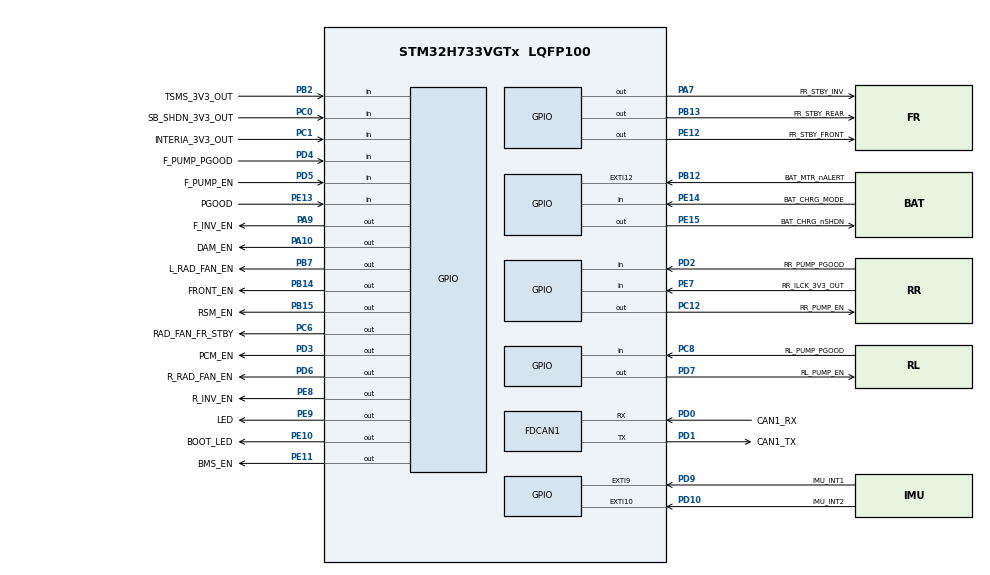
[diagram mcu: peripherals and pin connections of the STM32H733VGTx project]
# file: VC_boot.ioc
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FDCAN1.AutoRetransmission=ENABLE
FDCAN1.CalculateBaudRateNominal=1000000
FDCAN1.CalculateTimeBitNominal=1000
FDCAN1.CalculateTimeQuantumNominal=62.5
FDCAN1.DataPrescaler=3
FDCAN1.DataSyncJumpWidth=2
FDCAN1.DataTimeSeg1=5
FDCAN1.DataTimeSeg2=2
FDCAN1.ExtFiltersNbr=1
FDCAN1.FrameFormat=FDCAN_FRAME_FD_NO_BRS
FDCAN1.NominalPrescaler=6
FDCAN1.NominalSyncJumpWidth=2
FDCAN1.NominalTimeSeg1=12
FDCAN1.NominalTimeSeg2=3
FDCAN1.ProtocolException=DISABLE
FDCAN1.RxBufferSize=FDCAN_DATA_BYTES_64
FDCAN1.RxFifo0ElmtSize=FDCAN_DATA_BYTES_64
FDCAN1.RxFifo0ElmtsNbr=1
FDCAN1.RxFifo1ElmtSize=FDCAN_DATA_BYTES_64
FDCAN1.RxFifo1ElmtsNbr=0
FDCAN1.StdFiltersNbr=1
FDCAN1.TxElmtSize=FDCAN_DATA_BYTES_64
FDCAN1.TxFifoQueueElmtsNbr=1
FREERTOS.Tasks01=interfaceTask,48,512,runInterfaceTask,Default,NULL,Static,InterfaceTaskBuffer,InterfaceTaskControlBlock;canTx,40,512,runCanTxTask,Default,NULL,Static,canTxTaskBuffer,canTxTaskControlBlock;tickTask,8,512,runTickTask,Default,NULL,Static,tickTaskBuffer,tickTaskControlBlock
FREERTOS.configUSE_NEWLIB_REENTRANT=1
Mcu.Family=STM32H7
Mcu.Name=STM32H733VGTx
Mcu.Package=LQFP100
Mcu.UserConstants=LSI_FREQUENCY,32000;IWDG_PRESCALER,4;IWDG_RESET_FREQUENCY,4
NVIC.FDCAN1_IT0_IRQn=true\:5\:0\:false\:false\:true\:true\:true\:true\:true
NVIC.FDCAN1_IT1_IRQn=true\:5\:0\:false\:false\:true\:true\:true\:true\:true
NVIC.PriorityGroup=NVIC_PRIORITYGROUP_4
NVIC.TIM2_IRQn=true\:15\:0\:false\:false\:true\:false\:false\:true\:true
NVIC.TimeBase=TIM2_IRQn
NVIC.TimeBaseIP=TIM2
PA10.GPIO_Label=DAM_EN
PA10.Signal=GPIO_Output
PA13(JTMS/SWDIO).GPIO_Label=SWDIO_1
PA13(JTMS/SWDIO).Mode=Trace_Asynchronous_SW
PA13(JTMS/SWDIO).Signal=DEBUG_JTMS-SWDIO
PA14(JTCK/SWCLK).GPIO_Label=SWCLK_1
PA14(JTCK/SWCLK).Mode=Trace_Asynchronous_SW
PA14(JTCK/SWCLK).Signal=DEBUG_JTCK-SWCLK
PA7.GPIO_Label=FR_STBY_INV
PA7.Signal=GPIO_Output
PA9.GPIO_Label=F_INV_EN
PA9.Signal=GPIO_Output
PB12.GPIO_Label=BAT_MTR_nALERT
PB12.Signal=GPXTI12
PB13.GPIO_Label=FR_STBY_REAR
PB13.Signal=GPIO_Output
PB14.GPIO_Label=FRONT_EN
PB14.Signal=GPIO_Output
PB15.GPIO_Label=RSM_EN
PB15.Signal=GPIO_Output
PB2.GPIO_Label=TSMS_3V3_OUT
PB2.Signal=GPIO_Input
PB3(JTDO/TRACESWO).GPIO_Label=SWO1
PB3(JTDO/TRACESWO).Mode=Trace_Asynchronous_SW
PB3(JTDO/TRACESWO).Signal=DEBUG_JTDO-SWO
PB7.GPIO_Label=L_RAD_FAN_EN
PB7.Signal=GPIO_Output
PC0.GPIO_Label=SB_SHDN_3V3_OUT
PC0.Signal=GPIO_Input
PC1.GPIO_Label=INTERIA_3V3_OUT
PC1.Signal=GPIO_Input
PC12.GPIO_Label=RR_PUMP_EN
PC12.Signal=GPIO_Output
PC6.GPIO_Label=RAD_FAN_FR_STBY
PC6.Signal=GPIO_Output
PC8.GPIO_Label=RL_PUMP_PGOOD
PC8.Signal=GPIO_Input
PD0.GPIO_Label=CAN1_RX
PD0.Mode=FDCAN_Activate
PD0.Signal=FDCAN1_RX
PD1.GPIO_Label=CAN1_TX
PD1.Mode=FDCAN_Activate
PD1.Signal=FDCAN1_TX
PD10.GPIO_Label=IMU_INT2
PD10.Signal=GPXTI10
PD2.GPIO_Label=RR_PUMP_PGOOD
PD2.Signal=GPIO_Input
PD3.GPIO_Label=PCM_EN
PD3.Signal=GPIO_Output
PD4.GPIO_Label=F_PUMP_PGOOD
PD4.Signal=GPIO_Input
PD5.GPIO_Label=F_PUMP_EN
PD5.Signal=GPIO_Input
PD6.GPIO_Label=R_RAD_FAN_EN
PD6.Signal=GPIO_Output
PD7.GPIO_Label=RL_PUMP_EN
PD7.Signal=GPIO_Output
PD9.GPIO_Label=IMU_INT1
PD9.Signal=GPXTI9
PE10.GPIO_Label=BOOT_LED
PE10.PinState=GPIO_PIN_SET
PE10.Signal=GPIO_Output
PE11.GPIO_Label=BMS_EN
PE11.Signal=GPIO_Output
PE12.GPIO_Label=FR_STBY_FRONT
PE12.Signal=GPIO_Output
PE13.GPIO_Label=PGOOD
PE13.Signal=GPIO_Input
PE14.GPIO_Label=BAT_CHRG_MODE
PE14.Signal=GPIO_Input
PE15.GPIO_Label=BAT_CHRG_nSHDN
PE15.PinState=GPIO_PIN_SET
PE15.Signal=GPIO_Output
PE7.GPIO_Label=RR_ILCK_3V3_OUT
PE7.Signal=GPIO_Input
PE8.GPIO_Label=R_INV_EN
PE8.Signal=GPIO_Output
PE9.GPIO_Label=LED
PE9.Signal=GPIO_Output
PH0-OSC_IN.Mode=HSE-External-Oscillator
PH0-OSC_IN.Signal=RCC_OSC_IN
PH1-OSC_OUT.Mode=HSE-External-Oscillator
PH1-OSC_OUT.Signal=RCC_OSC_OUT
ProjectManager.HeapSize=0x200
ProjectManager.StackSize=0x400
ProjectManager.TargetToolchain=EWARM V8.50
RCC.ADCCLockSelection=RCC_ADCCLKSOURCE_PLL3
RCC.ADCFreq_Value=96000000
RCC.APB1Freq_Value=128000000
RCC.APB2Freq_Value=128000000
RCC.APB3Freq_Value=128000000
RCC.APB4Freq_Value=128000000
RCC.CortexFreq_Value=512000000
RCC.D1PPRE=RCC_APB3_DIV2
RCC.D2PPRE1=RCC_APB1_DIV2
RCC.D2PPRE2=RCC_APB2_DIV2
RCC.D3PPRE=RCC_APB4_DIV2
RCC.DIVM1=1
RCC.DIVM2=1
RCC.DIVM3=1
RCC.DIVN1=64
RCC.DIVN2=24
RCC.DIVN3=24
RCC.DIVP1=1
RCC.DIVQ3=4
RCC.FDCANCLockSelection=RCC_FDCANCLKSOURCE_PLL2
RCC.HCLKFreq_Value=256000000
RCC.HPRE=RCC_HCLK_DIV2
RCC.HSE_VALUE=8000000
RCC.PLL2FRACN=0
RCC.PLL3FRACN=0
RCC.PLLSourceVirtual=RCC_PLLSOURCE_HSE
RCC.SYSCLKFreq_VALUE=512000000
RCC.SYSCLKSource=RCC_SYSCLKSOURCE_PLLCLK
RCC.USBCLockSelection=RCC_USBCLKSOURCE_PLL3
RCC.USBFreq_Value=48000000
VP_FREERTOS_VS_CMSIS_V2.Mode=CMSIS_V2
VP_MEMORYMAP_VS_MEMORYMAP.Mode=CurAppReg
VP_SYS_VS_tim2.Mode=TIM2
board=custom

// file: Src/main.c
/* USER CODE BEGIN Header */
/**
 ******************************************************************************
 * @file           : main.c
 * @brief          : Main program body
 ******************************************************************************
 * @attention
 *
 * Copyright (c) 2024 STMicroelectronics.
 * All rights reserved.
 *
 * This software is licensed under terms that can be found in the LICENSE file
 * in the root directory of this software component.
 * If no LICENSE file comes with this software, it is provided AS-IS.
 *
 ******************************************************************************
 */
/* USER CODE END Header */
#include "main.h"
#include "cmsis_os.h"

/* USER CODE BEGIN Includes */
#include "hw/fdcan.h"
#include "bootloader.h"
#include "io/canQueue.h"
#include "hw/error.h"
/* USER CODE END Includes */

typedef StaticTask_t osStaticThreadDef_t;

FDCAN_HandleTypeDef hfdcan1;

/* Definitions for interfaceTask */
osThreadId_t         interfaceTaskHandle;
uint32_t             InterfaceTaskBuffer[512];
osStaticThreadDef_t  InterfaceTaskControlBlock;
const osThreadAttr_t interfaceTask_attributes = {
    .name       = "interfaceTask",
    .cb_mem     = &InterfaceTaskControlBlock,
    .cb_size    = sizeof(InterfaceTaskControlBlock),
    .stack_mem  = &InterfaceTaskBuffer[0],
    .stack_size = sizeof(InterfaceTaskBuffer),
    .priority   = (osPriority_t)osPriorityRealtime,
};
/* Definitions for canTx */
osThreadId_t         canTxHandle;
uint32_t             canTxTaskBuffer[512];
osStaticThreadDef_t  canTxTaskControlBlock;
const osThreadAttr_t canTx_attributes = {
    .name       = "canTx",
    .cb_mem     = &canTxTaskControlBlock,
    .cb_size    = sizeof(canTxTaskControlBlock),
    .stack_mem  = &canTxTaskBuffer[0],
    .stack_size = sizeof(canTxTaskBuffer),
    .priority   = (osPriority_t)osPriorityHigh,
};
/* Definitions for tickTask */
osThreadId_t         tickTaskHandle;
uint32_t             tickTaskBuffer[512];
osStaticThreadDef_t  tickTaskControlBlock;
const osThreadAttr_t tickTask_attributes = {
    .name       = "tickTask",
    .cb_mem     = &tickTaskControlBlock,
    .cb_size    = sizeof(tickTaskControlBlock),
    .stack_mem  = &tickTaskBuffer[0],
    .stack_size = sizeof(tickTaskBuffer),
    .priority   = (osPriority_t)osPriorityLow,
};
/* USER CODE BEGIN PV */
CanHandle can = { .hcan = &hfdcan1, .bus_num = 1, .receive_callback = io_canQueue_pushRx };
/* USER CODE END PV */

void        SystemClock_Config(void);
static void MX_GPIO_Init(void);
static void MX_FDCAN1_Init(void);
void        runInterfaceTask(void *argument);
void        runCanTxTask(void *argument);
void        runTickTask(void *argument);

int main(void)
{
    /* USER CODE BEGIN 1 */
    bootloader_preInit();
    /* USER CODE END 1 */

    /* MCU Configuration--------------------------------------------------------*/

    /* Reset of all peripherals, Initializes the Flash interface and the Systick. */
    HAL_Init();

    /* Configure the system clock */
    SystemClock_Config();

    /* Initialize all configured peripherals */
    MX_GPIO_Init();
    MX_FDCAN1_Init();
    /* USER CODE BEGIN 2 */
    HAL_GPIO_WritePin(BAT_CHRG_nSHDN_GPIO_Port, BAT_CHRG_nSHDN_Pin, false);

    bootloader_init();
    /* USER CODE END 2 */

    /* Init scheduler */
    osKernelInitialize();

    /* Create the thread(s) */
    /* creation of interfaceTask */
    interfaceTaskHandle = osThreadNew(runInterfaceTask, NULL, &interfaceTask_attributes);

    /* creation of canTx */
    canTxHandle = osThreadNew(runCanTxTask, NULL, &canTx_attributes);

    /* creation of tickTask */
    tickTaskHandle = osThreadNew(runTickTask, NULL, &tickTask_attributes);

    /* Start scheduler */
    osKernelStart();

    /* We should never get here as control is now taken by the scheduler */

    /* Infinite loop */
    while (1)
    {

    }
}

void SystemClock_Config(void)
{
    RCC_OscInitTypeDef RCC_OscInitStruct = { 0 };
    RCC_ClkInitTypeDef RCC_ClkInitStruct = { 0 };

    /** Supply configuration update enable
     */
    HAL_PWREx_ConfigSupply(PWR_LDO_SUPPLY);

    /** Configure the main internal regulator output voltage
     */
    __HAL_PWR_VOLTAGESCALING_CONFIG(PWR_REGULATOR_VOLTAGE_SCALE0);

    while (!__HAL_PWR_GET_FLAG(PWR_FLAG_VOSRDY))
    {
    }

    /** Initializes the RCC Oscillators according to the specified parameters
     * in the RCC_OscInitTypeDef structure.
     */
    RCC_OscInitStruct.OscillatorType = RCC_OSCILLATORTYPE_HSE;
    RCC_OscInitStruct.HSEState       = RCC_HSE_ON;
    RCC_OscInitStruct.PLL.PLLState   = RCC_PLL_ON;
    RCC_OscInitStruct.PLL.PLLSource  = RCC_PLLSOURCE_HSE;
    RCC_OscInitStruct.PLL.PLLM       = 1;
    RCC_OscInitStruct.PLL.PLLN       = 64;
    RCC_OscInitStruct.PLL.PLLP       = 1;
    RCC_OscInitStruct.PLL.PLLQ       = 2;
    RCC_OscInitStruct.PLL.PLLR       = 2;
    RCC_OscInitStruct.PLL.PLLRGE     = RCC_PLL1VCIRANGE_3;
    RCC_OscInitStruct.PLL.PLLVCOSEL  = RCC_PLL1VCOWIDE;
    RCC_OscInitStruct.PLL.PLLFRACN   = 0;
    if (HAL_RCC_OscConfig(&RCC_OscInitStruct) != HAL_OK)
    {
        Error_Handler();
    }

    /** Initializes the CPU, AHB and APB buses clocks
     */
    RCC_ClkInitStruct.ClockType = RCC_CLOCKTYPE_HCLK | RCC_CLOCKTYPE_SYSCLK | RCC_CLOCKTYPE_PCLK1 |
                                  RCC_CLOCKTYPE_PCLK2 | RCC_CLOCKTYPE_D3PCLK1 | RCC_CLOCKTYPE_D1PCLK1;
    RCC_ClkInitStruct.SYSCLKSource   = RCC_SYSCLKSOURCE_PLLCLK;
    RCC_ClkInitStruct.SYSCLKDivider  = RCC_SYSCLK_DIV1;
    RCC_ClkInitStruct.AHBCLKDivider  = RCC_HCLK_DIV2;
    RCC_ClkInitStruct.APB3CLKDivider = RCC_APB3_DIV2;
    RCC_ClkInitStruct.APB1CLKDivider = RCC_APB1_DIV2;
    RCC_ClkInitStruct.APB2CLKDivider = RCC_APB2_DIV2;
    RCC_ClkInitStruct.APB4CLKDivider = RCC_APB4_DIV2;

    if (HAL_RCC_ClockConfig(&RCC_ClkInitStruct, FLASH_LATENCY_3) != HAL_OK)
    {
        Error_Handler();
    }
}

static void MX_FDCAN1_Init(void)
{

    hfdcan1.Instance                  = FDCAN1;
    hfdcan1.Init.FrameFormat          = FDCAN_FRAME_FD_NO_BRS;
    hfdcan1.Init.Mode                 = FDCAN_MODE_NORMAL;
    hfdcan1.Init.AutoRetransmission   = ENABLE;
    hfdcan1.Init.TransmitPause        = DISABLE;
    hfdcan1.Init.ProtocolException    = DISABLE;
    hfdcan1.Init.NominalPrescaler     = 6;
    hfdcan1.Init.NominalSyncJumpWidth = 2;
    hfdcan1.Init.NominalTimeSeg1      = 12;
    hfdcan1.Init.NominalTimeSeg2      = 3;
    hfdcan1.Init.DataPrescaler        = 3;
    hfdcan1.Init.DataSyncJumpWidth    = 2;
    hfdcan1.Init.DataTimeSeg1         = 5;
    hfdcan1.Init.DataTimeSeg2         = 2;
    hfdcan1.Init.MessageRAMOffset     = 0;
    hfdcan1.Init.StdFiltersNbr        = 1;
    hfdcan1.Init.ExtFiltersNbr        = 1;
    hfdcan1.Init.RxFifo0ElmtsNbr      = 1;
    hfdcan1.Init.RxFifo0ElmtSize      = FDCAN_DATA_BYTES_64;
    hfdcan1.Init.RxFifo1ElmtsNbr      = 0;
    hfdcan1.Init.RxFifo1ElmtSize      = FDCAN_DATA_BYTES_64;
    hfdcan1.Init.RxBuffersNbr         = 0;
    hfdcan1.Init.RxBufferSize         = FDCAN_DATA_BYTES_64;
    hfdcan1.Init.TxEventsNbr          = 0;
    hfdcan1.Init.TxBuffersNbr         = 0;
    hfdcan1.Init.TxFifoQueueElmtsNbr  = 1;
    hfdcan1.Init.TxFifoQueueMode      = FDCAN_TX_FIFO_OPERATION;
    hfdcan1.Init.TxElmtSize           = FDCAN_DATA_BYTES_64;
    if (HAL_FDCAN_Init(&hfdcan1) != HAL_OK)
    {
        Error_Handler();
    }
}

static void MX_GPIO_Init(void)
{
    GPIO_InitTypeDef GPIO_InitStruct = { 0 };

    /* GPIO Ports Clock Enable */
    __HAL_RCC_GPIOH_CLK_ENABLE();
    __HAL_RCC_GPIOC_CLK_ENABLE();
    __HAL_RCC_GPIOA_CLK_ENABLE();
    __HAL_RCC_GPIOB_CLK_ENABLE();
    __HAL_RCC_GPIOE_CLK_ENABLE();
    __HAL_RCC_GPIOD_CLK_ENABLE();

    /*Configure GPIO pin Output Level */
    HAL_GPIO_WritePin(GPIOA, FR_STBY_INV_Pin | F_INV_EN_Pin | DAM_EN_Pin, GPIO_PIN_RESET);

    /*Configure GPIO pin Output Level */
    HAL_GPIO_WritePin(GPIOE, R_INV_EN_Pin | LED_Pin | BMS_EN_Pin | FR_STBY_FRONT_Pin, GPIO_PIN_RESET);

    /*Configure GPIO pin Output Level */
    HAL_GPIO_WritePin(GPIOE, BOOT_LED_Pin | BAT_CHRG_nSHDN_Pin, GPIO_PIN_SET);

    /*Configure GPIO pin Output Level */
    HAL_GPIO_WritePin(GPIOB, FR_STBY_REAR_Pin | FRONT_EN_Pin | RSM_EN_Pin | L_RAD_FAN_EN_Pin, GPIO_PIN_RESET);

    /*Configure GPIO pin Output Level */
    HAL_GPIO_WritePin(GPIOC, RAD_FAN_FR_STBY_Pin | RR_PUMP_EN_Pin, GPIO_PIN_RESET);

    /*Configure GPIO pin Output Level */
    HAL_GPIO_WritePin(GPIOD, PCM_EN_Pin | R_RAD_FAN_EN_Pin | RL_PUMP_EN_Pin, GPIO_PIN_RESET);

    /*Configure GPIO pins : SB_SHDN_3V3_OUT_Pin INTERIA_3V3_OUT_Pin RL_PUMP_PGOOD_Pin */
    GPIO_InitStruct.Pin  = SB_SHDN_3V3_OUT_Pin | INTERIA_3V3_OUT_Pin | RL_PUMP_PGOOD_Pin;
    GPIO_InitStruct.Mode = GPIO_MODE_INPUT;
    GPIO_InitStruct.Pull = GPIO_NOPULL;
    HAL_GPIO_Init(GPIOC, &GPIO_InitStruct);

    /*Configure GPIO pins : FR_STBY_INV_Pin F_INV_EN_Pin DAM_EN_Pin */
    GPIO_InitStruct.Pin   = FR_STBY_INV_Pin | F_INV_EN_Pin | DAM_EN_Pin;
    GPIO_InitStruct.Mode  = GPIO_MODE_OUTPUT_PP;
    GPIO_InitStruct.Pull  = GPIO_NOPULL;
    GPIO_InitStruct.Speed = GPIO_SPEED_FREQ_LOW;
    HAL_GPIO_Init(GPIOA, &GPIO_InitStruct);

    /*Configure GPIO pin : TSMS_3V3_OUT_Pin */
    GPIO_InitStruct.Pin  = TSMS_3V3_OUT_Pin;
    GPIO_InitStruct.Mode = GPIO_MODE_INPUT;
    GPIO_InitStruct.Pull = GPIO_NOPULL;
    HAL_GPIO_Init(TSMS_3V3_OUT_GPIO_Port, &GPIO_InitStruct);

    /*Configure GPIO pins : RR_ILCK_3V3_OUT_Pin PGOOD_Pin BAT_CHRG_MODE_Pin */
    GPIO_InitStruct.Pin  = RR_ILCK_3V3_OUT_Pin | PGOOD_Pin | BAT_CHRG_MODE_Pin;
    GPIO_InitStruct.Mode = GPIO_MODE_INPUT;
    GPIO_InitStruct.Pull = GPIO_NOPULL;
    HAL_GPIO_Init(GPIOE, &GPIO_InitStruct);

    /*Configure GPIO pins : R_INV_EN_Pin LED_Pin BOOT_LED_Pin BMS_EN_Pin
                             FR_STBY_FRONT_Pin BAT_CHRG_nSHDN_Pin */
    GPIO_InitStruct.Pin   = R_INV_EN_Pin | LED_Pin | BOOT_LED_Pin | BMS_EN_Pin | FR_STBY_FRONT_Pin | BAT_CHRG_nSHDN_Pin;
    GPIO_InitStruct.Mode  = GPIO_MODE_OUTPUT_PP;
    GPIO_InitStruct.Pull  = GPIO_NOPULL;
    GPIO_InitStruct.Speed = GPIO_SPEED_FREQ_LOW;
    HAL_GPIO_Init(GPIOE, &GPIO_InitStruct);

    /*Configure GPIO pin : BAT_MTR_nALERT_Pin */
    GPIO_InitStruct.Pin  = BAT_MTR_nALERT_Pin;
    GPIO_InitStruct.Mode = GPIO_MODE_IT_RISING;
    GPIO_InitStruct.Pull = GPIO_NOPULL;
    HAL_GPIO_Init(BAT_MTR_nALERT_GPIO_Port, &GPIO_InitStruct);

    /*Configure GPIO pins : FR_STBY_REAR_Pin FRONT_EN_Pin RSM_EN_Pin L_RAD_FAN_EN_Pin */
    GPIO_InitStruct.Pin   = FR_STBY_REAR_Pin | FRONT_EN_Pin | RSM_EN_Pin | L_RAD_FAN_EN_Pin;
    GPIO_InitStruct.Mode  = GPIO_MODE_OUTPUT_PP;
    GPIO_InitStruct.Pull  = GPIO_NOPULL;
    GPIO_InitStruct.Speed = GPIO_SPEED_FREQ_LOW;
    HAL_GPIO_Init(GPIOB, &GPIO_InitStruct);

    /*Configure GPIO pins : IMU_INT1_Pin IMU_INT2_Pin */
    GPIO_InitStruct.Pin  = IMU_INT1_Pin | IMU_INT2_Pin;
    GPIO_InitStruct.Mode = GPIO_MODE_IT_RISING;
    GPIO_InitStruct.Pull = GPIO_NOPULL;
    HAL_GPIO_Init(GPIOD, &GPIO_InitStruct);

    /*Configure GPIO pins : RAD_FAN_FR_STBY_Pin RR_PUMP_EN_Pin */
    GPIO_InitStruct.Pin   = RAD_FAN_FR_STBY_Pin | RR_PUMP_EN_Pin;
    GPIO_InitStruct.Mode  = GPIO_MODE_OUTPUT_PP;
    GPIO_InitStruct.Pull  = GPIO_NOPULL;
    GPIO_InitStruct.Speed = GPIO_SPEED_FREQ_LOW;
    HAL_GPIO_Init(GPIOC, &GPIO_InitStruct);

    /*Configure GPIO pins : RR_PUMP_PGOOD_Pin F_PUMP_PGOOD_Pin F_PUMP_EN_Pin */
    GPIO_InitStruct.Pin  = RR_PUMP_PGOOD_Pin | F_PUMP_PGOOD_Pin | F_PUMP_EN_Pin;
    GPIO_InitStruct.Mode = GPIO_MODE_INPUT;
    GPIO_InitStruct.Pull = GPIO_NOPULL;
    HAL_GPIO_Init(GPIOD, &GPIO_InitStruct);

    /*Configure GPIO pins : PCM_EN_Pin R_RAD_FAN_EN_Pin RL_PUMP_EN_Pin */
    GPIO_InitStruct.Pin   = PCM_EN_Pin | R_RAD_FAN_EN_Pin | RL_PUMP_EN_Pin;
    GPIO_InitStruct.Mode  = GPIO_MODE_OUTPUT_PP;
    GPIO_InitStruct.Pull  = GPIO_NOPULL;
    GPIO_InitStruct.Speed = GPIO_SPEED_FREQ_LOW;
    HAL_GPIO_Init(GPIOD, &GPIO_InitStruct);

}

void runInterfaceTask(void *argument)
{
    /* USER CODE BEGIN 5 */
    /* Infinite loop */
    bootloader_runInterfaceTask();
    /* USER CODE END 5 */
}

void runCanTxTask(void *argument)
{
    /* USER CODE BEGIN runCanTxTask */
    /* Infinite loop */
    bootloader_runCanTxTask();
    /* USER CODE END runCanTxTask */
}

void runTickTask(void *argument)
{
    /* USER CODE BEGIN runTickTask */
    /* Infinite loop */
    bootloader_runTickTask();
    /* USER CODE END runTickTask */
}

void HAL_TIM_PeriodElapsedCallback(TIM_HandleTypeDef *htim)
{
    if (htim->Instance == TIM2)
    {
        HAL_IncTick();
    }
}

void Error_Handler(void)
{
    __disable_irq();
    while (1)
    {
    }
}
